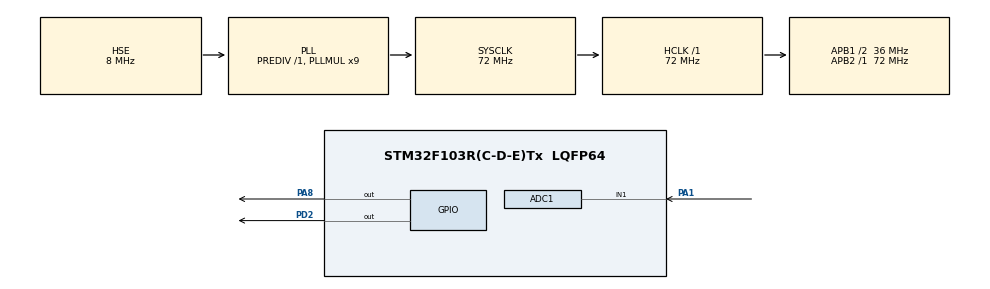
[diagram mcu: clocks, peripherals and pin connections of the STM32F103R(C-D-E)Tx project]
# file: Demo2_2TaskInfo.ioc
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ADC1.Channel-0\#ChannelRegularConversion=ADC_CHANNEL_1
ADC1.NbrOfConversionFlag=1
ADC1.Rank-0\#ChannelRegularConversion=1
ADC1.SamplingTime-0\#ChannelRegularConversion=ADC_SAMPLETIME_1CYCLE_5
ADC1.master=1
FREERTOS.Tasks01=Task_ADC,24,256,App_ADC,Default,NULL,Dynamic,NULL,NULL;Task_Info,8,256,App_Info,Default,NULL,Dynamic,NULL,NULL
Mcu.Family=STM32F1
Mcu.Name=STM32F103R(C-D-E)Tx
Mcu.Package=LQFP64
NVIC.PriorityGroup=NVIC_PRIORITYGROUP_4
NVIC.TIM6_IRQn=true\:15\:0\:false\:false\:true\:false\:false\:true\:true
NVIC.TimeBase=TIM6_IRQn
NVIC.TimeBaseIP=TIM6
PA1.Signal=ADCx_IN1
PA13.Mode=Serial_Wire
PA13.Signal=SYS_JTMS-SWDIO
PA14.Mode=Serial_Wire
PA14.Signal=SYS_JTCK-SWCLK
PA8.Signal=GPIO_Output
PC14-OSC32_IN.Mode=LSE-External-Oscillator
PC14-OSC32_IN.Signal=RCC_OSC32_IN
PC15-OSC32_OUT.Mode=LSE-External-Oscillator
PC15-OSC32_OUT.Signal=RCC_OSC32_OUT
PD0-OSC_IN.Mode=HSE-External-Oscillator
PD0-OSC_IN.Signal=RCC_OSC_IN
PD1-OSC_OUT.Mode=HSE-External-Oscillator
PD1-OSC_OUT.Signal=RCC_OSC_OUT
PD2.Signal=GPIO_Output
ProjectManager.HeapSize=0x200
ProjectManager.StackSize=0x400
ProjectManager.TargetToolchain=SW4STM32
RCC.ADCPresc=RCC_ADCPCLK2_DIV6
RCC.AHBFreq_Value=72000000
RCC.APB1CLKDivider=RCC_HCLK_DIV2
RCC.APB1Freq_Value=36000000
RCC.APB1TimFreq_Value=72000000
RCC.APB2Freq_Value=72000000
RCC.APB2TimFreq_Value=72000000
RCC.HCLKFreq_Value=72000000
RCC.PLLMUL=RCC_PLL_MUL9
RCC.PLLSourceVirtual=RCC_PLLSOURCE_HSE
RCC.SYSCLKFreq_VALUE=72000000
RCC.SYSCLKSource=RCC_SYSCLKSOURCE_PLLCLK
RCC.USBFreq_Value=72000000
SH.ADCx_IN1.0=ADC1_IN1,IN1
VP_FREERTOS_VS_CMSIS_V2.Mode=CMSIS_V2
VP_SYS_VS_tim6.Mode=TIM6
board=custom

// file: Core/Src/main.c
/* USER CODE BEGIN Header */
/**
  ******************************************************************************
  * @file           : main.c
  * @brief          : Main program body
  ******************************************************************************
  * @attention
  *
  * Copyright (c) 2022 STMicroelectronics.
  * All rights reserved.
  *
  * This software is licensed under terms that can be found in the LICENSE file
  * in the root directory of this software component.
  * If no LICENSE file comes with this software, it is provided AS-IS.
  *
  ******************************************************************************
  */
/* USER CODE END Header */
#include "main.h"
#include "cmsis_os.h"
#include "adc.h"
#include "gpio.h"

/* USER CODE BEGIN Includes */
#include "lcd.h"
/* USER CODE END Includes */

void SystemClock_Config(void);
void MX_FREERTOS_Init(void);

int main(void)
{

  /* MCU Configuration--------------------------------------------------------*/

  /* Reset of all peripherals, Initializes the Flash interface and the Systick. */
  HAL_Init();

  /* USER CODE BEGIN Init */
  LCD_Init();
  /* USER CODE END Init */

  /* Configure the system clock */
  SystemClock_Config();

  /* Initialize all configured peripherals */
  MX_GPIO_Init();
  MX_ADC1_Init();
  /* USER CODE BEGIN 2 */
  POINT_COLOR=BLUE;
  LCD_ShowString(10,10,200,24,16,(uint8_t *)"Demo2_2:Task Utilities");
  /* USER CODE END 2 */

  /* Init scheduler */
  osKernelInitialize();  /* Call init function for freertos objects (in freertos.c) */
  MX_FREERTOS_Init();

  /* Start scheduler */
  osKernelStart();

  /* We should never get here as control is now taken by the scheduler */
  /* Infinite loop */
  while (1)
  {

  }
}

void SystemClock_Config(void)
{
  RCC_OscInitTypeDef RCC_OscInitStruct = {0};
  RCC_ClkInitTypeDef RCC_ClkInitStruct = {0};
  RCC_PeriphCLKInitTypeDef PeriphClkInit = {0};

  /** Initializes the RCC Oscillators according to the specified parameters
  * in the RCC_OscInitTypeDef structure.
  */
  RCC_OscInitStruct.OscillatorType = RCC_OSCILLATORTYPE_HSE;
  RCC_OscInitStruct.HSEState = RCC_HSE_ON;
  RCC_OscInitStruct.HSEPredivValue = RCC_HSE_PREDIV_DIV1;
  RCC_OscInitStruct.HSIState = RCC_HSI_ON;
  RCC_OscInitStruct.PLL.PLLState = RCC_PLL_ON;
  RCC_OscInitStruct.PLL.PLLSource = RCC_PLLSOURCE_HSE;
  RCC_OscInitStruct.PLL.PLLMUL = RCC_PLL_MUL9;
  if (HAL_RCC_OscConfig(&RCC_OscInitStruct) != HAL_OK)
  {
    Error_Handler();
  }

  /** Initializes the CPU, AHB and APB buses clocks
  */
  RCC_ClkInitStruct.ClockType = RCC_CLOCKTYPE_HCLK|RCC_CLOCKTYPE_SYSCLK
                              |RCC_CLOCKTYPE_PCLK1|RCC_CLOCKTYPE_PCLK2;
  RCC_ClkInitStruct.SYSCLKSource = RCC_SYSCLKSOURCE_PLLCLK;
  RCC_ClkInitStruct.AHBCLKDivider = RCC_SYSCLK_DIV1;
  RCC_ClkInitStruct.APB1CLKDivider = RCC_HCLK_DIV2;
  RCC_ClkInitStruct.APB2CLKDivider = RCC_HCLK_DIV1;

  if (HAL_RCC_ClockConfig(&RCC_ClkInitStruct, FLASH_LATENCY_2) != HAL_OK)
  {
    Error_Handler();
  }
  PeriphClkInit.PeriphClockSelection = RCC_PERIPHCLK_ADC;
  PeriphClkInit.AdcClockSelection = RCC_ADCPCLK2_DIV6;
  if (HAL_RCCEx_PeriphCLKConfig(&PeriphClkInit) != HAL_OK)
  {
    Error_Handler();
  }
}

void HAL_TIM_PeriodElapsedCallback(TIM_HandleTypeDef *htim)
{
  if (htim->Instance == TIM6) {
    HAL_IncTick();
  }
}

void Error_Handler(void)
{
  __disable_irq();
  while (1)
  {
  }
}

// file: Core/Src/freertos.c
/* USER CODE BEGIN Header */
/**
  ******************************************************************************
  * File Name          : freertos.c
  * Description        : Code for freertos applications
  ******************************************************************************
  * @attention
  *
  * Copyright (c) 2022 STMicroelectronics.
  * All rights reserved.
  *
  * This software is licensed under terms that can be found in the LICENSE file
  * in the root directory of this software component.
  * If no LICENSE file comes with this software, it is provided AS-IS.
  *
  ******************************************************************************
  */
/* USER CODE END Header */

#include "FreeRTOS.h"
#include "task.h"
#include "main.h"
#include "cmsis_os.h"

/* USER CODE BEGIN Includes */
#include "lcd.h"
#include "adc.h"
#include "stdio.h"
/* USER CODE END Includes */

/* Definitions for Task_ADC */
osThreadId_t Task_ADCHandle;
const osThreadAttr_t Task_ADC_attributes = {
  .name = "Task_ADC",
  .stack_size = 256 * 4,
  .priority = (osPriority_t) osPriorityNormal,
};
/* Definitions for Task_Info */
osThreadId_t Task_InfoHandle;
const osThreadAttr_t Task_Info_attributes = {
  .name = "Task_Info",
  .stack_size = 256 * 4,
  .priority = (osPriority_t) osPriorityLow,
};

void App_ADC(void *argument);
void App_Info(void *argument);

void MX_FREERTOS_Init(void); /* (MISRA C 2004 rule 8.1) */

void MX_FREERTOS_Init(void) {

  /* Create the thread(s) */
  /* creation of Task_ADC */
  Task_ADCHandle = osThreadNew(App_ADC, NULL, &Task_ADC_attributes);

  /* creation of Task_Info */
  Task_InfoHandle = osThreadNew(App_Info, NULL, &Task_Info_attributes);

}

void App_ADC(void *argument)
{
  /* USER CODE BEGIN App_ADC */
  char ADC_Value[10];
  LCD_ShowString(10,40,200,24,16,(uint8_t *)"Task:ADC:ADC by polling");
  LCD_ShowString(10,60,200,24,16,(uint8_t *)"ADC Value(mV)=");

  TickType_t previousWakeTime=xTaskGetTickCount();

  /* Infinite loop */
  for(;;)
  {
      HAL_ADC_Start(&hadc1);
      if(HAL_ADC_PollForConversion(&hadc1,100)==HAL_OK)
      {
          uint32_t val= HAL_ADC_GetValue(&hadc1);
          //LCD_ShowxNum(125,60,val,4,16,0);
          uint32_t Volt=3300*val;
          Volt=Volt>>12;
          sprintf(ADC_Value,"%d",Volt);
          LCD_ShowString(125,60,200,24,16,(uint8_t *)ADC_Value);

      }
      vTaskDelayUntil(&previousWakeTime, pdMS_TO_TICKS(500));
  }
  /* USER CODE END App_ADC */
}

void App_Info(void *argument)
{
  /* USER CODE BEGIN App_Info */
  char str[8];
  TaskHandle_t taskHandle;
  UBaseType_t  hwm;
  POINT_COLOR=RED;

  taskHandle=Task_ADCHandle;
  hwm=uxTaskGetStackHighWaterMark(taskHandle);
  sprintf(str,"%d",hwm);
  LCD_ShowString(10,80,200,24,16,(uint8_t *)"High Water Mark of tasks:");
  LCD_ShowString(10,100,200,24,16,(uint8_t *)"Task_ADC= ");
  LCD_ShowString(100,100,200,24,16,(uint8_t *)str);

  taskHandle=Task_InfoHandle;
  hwm=uxTaskGetStackHighWaterMark(taskHandle);
  sprintf(str,"%d",hwm);
  LCD_ShowString(10,120,200,24,16,(uint8_t *)"Task_Info= ");
  LCD_ShowString(100,120,200,24,16,(uint8_t *)str);

  UBaseType_t loopCount=0;

  /* Infinite loop */
  for(;;)
  {
      loopCount++;
      HAL_GPIO_TogglePin(GPIOA,GPIO_PIN_8);
      vTaskDelay(pdMS_TO_TICKS(500));
      if (loopCount==10)
          break;
  }

  POINT_COLOR=BLACK;
    LCD_ShowString(10,140,200,24,16,(uint8_t *)"Task_Info is deleted");
    vTaskDelete(NULL);
  /* USER CODE END App_Info */
}
